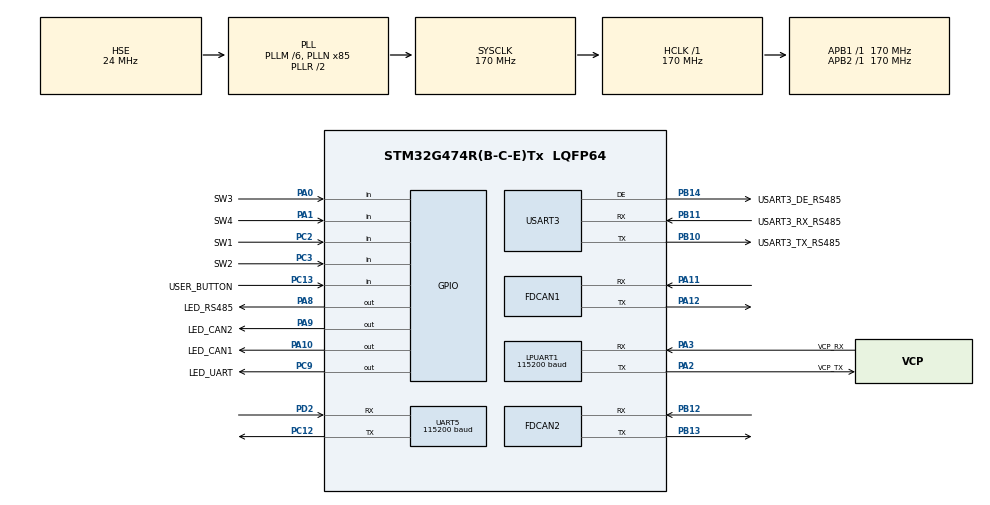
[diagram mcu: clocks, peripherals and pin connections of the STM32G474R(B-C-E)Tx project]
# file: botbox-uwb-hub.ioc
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Dma.Request0=USART3_RX
Dma.Request1=USART3_TX
Dma.Request2=UART5_RX
Dma.Request3=UART5_TX
Dma.UART5_RX.2.Direction=DMA_PERIPH_TO_MEMORY
Dma.UART5_RX.2.EventEnable=DISABLE
Dma.UART5_RX.2.Instance=DMA1_Channel3
Dma.UART5_RX.2.MemDataAlignment=DMA_MDATAALIGN_BYTE
Dma.UART5_RX.2.MemInc=DMA_MINC_ENABLE
Dma.UART5_RX.2.Mode=DMA_CIRCULAR
Dma.UART5_RX.2.PeriphDataAlignment=DMA_PDATAALIGN_BYTE
Dma.UART5_RX.2.PeriphInc=DMA_PINC_DISABLE
Dma.UART5_RX.2.Polarity=HAL_DMAMUX_REQ_GEN_RISING
Dma.UART5_RX.2.Priority=DMA_PRIORITY_LOW
Dma.UART5_RX.2.RequestNumber=1
Dma.UART5_RX.2.SignalID=NONE
Dma.UART5_RX.2.SyncEnable=DISABLE
Dma.UART5_RX.2.SyncPolarity=HAL_DMAMUX_SYNC_NO_EVENT
Dma.UART5_RX.2.SyncRequestNumber=1
Dma.UART5_RX.2.SyncSignalID=NONE
Dma.UART5_TX.3.Direction=DMA_MEMORY_TO_PERIPH
Dma.UART5_TX.3.EventEnable=DISABLE
Dma.UART5_TX.3.Instance=DMA1_Channel4
Dma.UART5_TX.3.MemDataAlignment=DMA_MDATAALIGN_BYTE
Dma.UART5_TX.3.MemInc=DMA_MINC_ENABLE
Dma.UART5_TX.3.Mode=DMA_NORMAL
Dma.UART5_TX.3.PeriphDataAlignment=DMA_PDATAALIGN_BYTE
Dma.UART5_TX.3.PeriphInc=DMA_PINC_DISABLE
Dma.UART5_TX.3.Polarity=HAL_DMAMUX_REQ_GEN_RISING
Dma.UART5_TX.3.Priority=DMA_PRIORITY_LOW
Dma.UART5_TX.3.RequestNumber=1
Dma.UART5_TX.3.SignalID=NONE
Dma.UART5_TX.3.SyncEnable=DISABLE
Dma.UART5_TX.3.SyncPolarity=HAL_DMAMUX_SYNC_NO_EVENT
Dma.UART5_TX.3.SyncRequestNumber=1
Dma.UART5_TX.3.SyncSignalID=NONE
Dma.USART3_RX.0.Direction=DMA_PERIPH_TO_MEMORY
Dma.USART3_RX.0.EventEnable=DISABLE
Dma.USART3_RX.0.Instance=DMA1_Channel1
Dma.USART3_RX.0.MemDataAlignment=DMA_MDATAALIGN_BYTE
Dma.USART3_RX.0.MemInc=DMA_MINC_ENABLE
Dma.USART3_RX.0.Mode=DMA_CIRCULAR
Dma.USART3_RX.0.PeriphDataAlignment=DMA_PDATAALIGN_BYTE
Dma.USART3_RX.0.PeriphInc=DMA_PINC_DISABLE
Dma.USART3_RX.0.Polarity=HAL_DMAMUX_REQ_GEN_RISING
Dma.USART3_RX.0.Priority=DMA_PRIORITY_LOW
Dma.USART3_RX.0.RequestNumber=1
Dma.USART3_RX.0.SignalID=NONE
Dma.USART3_RX.0.SyncEnable=DISABLE
Dma.USART3_RX.0.SyncPolarity=HAL_DMAMUX_SYNC_NO_EVENT
Dma.USART3_RX.0.SyncRequestNumber=1
Dma.USART3_RX.0.SyncSignalID=NONE
Dma.USART3_TX.1.Direction=DMA_MEMORY_TO_PERIPH
Dma.USART3_TX.1.EventEnable=DISABLE
Dma.USART3_TX.1.Instance=DMA1_Channel2
Dma.USART3_TX.1.MemDataAlignment=DMA_MDATAALIGN_BYTE
Dma.USART3_TX.1.MemInc=DMA_MINC_ENABLE
Dma.USART3_TX.1.Mode=DMA_NORMAL
Dma.USART3_TX.1.PeriphDataAlignment=DMA_PDATAALIGN_BYTE
Dma.USART3_TX.1.PeriphInc=DMA_PINC_DISABLE
Dma.USART3_TX.1.Polarity=HAL_DMAMUX_REQ_GEN_RISING
Dma.USART3_TX.1.Priority=DMA_PRIORITY_LOW
Dma.USART3_TX.1.RequestNumber=1
Dma.USART3_TX.1.SignalID=NONE
Dma.USART3_TX.1.SyncEnable=DISABLE
Dma.USART3_TX.1.SyncPolarity=HAL_DMAMUX_SYNC_NO_EVENT
Dma.USART3_TX.1.SyncRequestNumber=1
Dma.USART3_TX.1.SyncSignalID=NONE
FDCAN1.AutoRetransmission=ENABLE
FDCAN1.CalculateBaudRateNominal=500000
FDCAN1.CalculateTimeBitNominal=2000
FDCAN1.CalculateTimeQuantumNominal=41.666666666666664
FDCAN1.DataPrescaler=1
FDCAN1.DataSyncJumpWidth=3
FDCAN1.DataTimeSeg1=8
FDCAN1.DataTimeSeg2=3
FDCAN1.ExtFiltersNbr=1
FDCAN1.FrameFormat=FDCAN_FRAME_FD_BRS
FDCAN1.NominalPrescaler=1
FDCAN1.NominalSyncJumpWidth=10
FDCAN1.NominalTimeSeg1=37
FDCAN1.NominalTimeSeg2=10
FDCAN1.StdFiltersNbr=1
FDCAN2.AutoRetransmission=ENABLE
FDCAN2.CalculateBaudRateNominal=500000
FDCAN2.CalculateTimeBitNominal=2000
FDCAN2.CalculateTimeQuantumNominal=41.666666666666664
FDCAN2.DataPrescaler=1
FDCAN2.DataSyncJumpWidth=3
FDCAN2.DataTimeSeg1=8
FDCAN2.DataTimeSeg2=3
FDCAN2.ExtFiltersNbr=1
FDCAN2.FrameFormat=FDCAN_FRAME_FD_BRS
FDCAN2.NominalPrescaler=1
FDCAN2.NominalSyncJumpWidth=10
FDCAN2.NominalTimeSeg1=37
FDCAN2.NominalTimeSeg2=10
FDCAN2.StdFiltersNbr=1
FREERTOS.Tasks01=defaultTask,24,128,StartDefaultTask,Default,NULL,Dynamic,NULL,NULL
FREERTOS.configCHECK_FOR_STACK_OVERFLOW=2
FREERTOS.configENABLE_FPU=1
FREERTOS.configTOTAL_HEAP_SIZE=24576
FREERTOS.configUSE_MALLOC_FAILED_HOOK=1
LPUART1.BaudRate=115200
Mcu.Family=STM32G4
Mcu.Name=STM32G474R(B-C-E)Tx
Mcu.Package=LQFP64
NVIC.DMA1_Channel1_IRQn=true\:6\:0\:true\:false\:true\:true\:false\:true\:true
NVIC.DMA1_Channel2_IRQn=true\:6\:0\:true\:false\:true\:true\:false\:true\:true
NVIC.DMA1_Channel3_IRQn=true\:6\:0\:true\:false\:true\:true\:false\:true\:true
NVIC.DMA1_Channel4_IRQn=true\:6\:0\:true\:false\:true\:true\:false\:true\:true
NVIC.FDCAN1_IT0_IRQn=true\:5\:0\:false\:false\:true\:true\:true\:true\:true
NVIC.FDCAN1_IT1_IRQn=true\:5\:0\:false\:false\:true\:true\:true\:true\:true
NVIC.FDCAN2_IT0_IRQn=true\:5\:0\:false\:false\:true\:true\:true\:true\:true
NVIC.FDCAN2_IT1_IRQn=true\:5\:0\:false\:false\:true\:true\:true\:true\:true
NVIC.PriorityGroup=NVIC_PRIORITYGROUP_4
NVIC.TIM7_DAC_IRQn=true\:15\:0\:false\:false\:true\:false\:false\:true\:true
NVIC.TimeBase=TIM7_DAC_IRQn
NVIC.TimeBaseIP=TIM7
NVIC.UART5_IRQn=true\:6\:0\:true\:false\:true\:true\:true\:true\:true
NVIC.USART3_IRQn=true\:6\:0\:true\:false\:true\:true\:true\:true\:true
PA0.GPIO_Label=SW3
PA0.Signal=GPIO_Input
PA1.GPIO_Label=SW4
PA1.Signal=GPIO_Input
PA10.GPIO_Label=LED_CAN1
PA10.Signal=GPIO_Output
PA11.Mode=FDCAN_Activate
PA11.Signal=FDCAN1_RX
PA12.Mode=FDCAN_Activate
PA12.Signal=FDCAN1_TX
PA13.Mode=Serial_Wire
PA13.Signal=SYS_JTMS-SWDIO
PA14.Mode=Serial_Wire
PA14.Signal=SYS_JTCK-SWCLK
PA2.GPIO_Label=VCP_TX
PA2.Mode=Asynchronous
PA2.Signal=LPUART1_TX
PA3.GPIO_Label=VCP_RX
PA3.Mode=Asynchronous
PA3.Signal=LPUART1_RX
PA8.GPIO_Label=LED_RS485
PA8.Signal=GPIO_Output
PA9.GPIO_Label=LED_CAN2
PA9.Signal=GPIO_Output
PB10.GPIO_Label=USART3_TX_RS485
PB10.Mode=Asynchronous
PB10.Signal=USART3_TX
PB11.GPIO_Label=USART3_RX_RS485
PB11.Mode=Asynchronous
PB11.Signal=USART3_RX
PB12.Mode=FDCAN_Activate
PB12.Signal=FDCAN2_RX
PB13.Mode=FDCAN_Activate
PB13.Signal=FDCAN2_TX
PB14.GPIO_Label=USART3_DE_RS485
PB14.Mode=Hardware Flow Control (RS485)
PB14.Signal=USART3_DE
PC12.Mode=Asynchronous
PC12.Signal=UART5_TX
PC13.GPIO_Label=USER_BUTTON
PC13.Signal=GPIO_Input
PC14-OSC32_IN.Mode=LSE-External-Oscillator
PC14-OSC32_IN.Signal=RCC_OSC32_IN
PC15-OSC32_OUT.Mode=LSE-External-Oscillator
PC15-OSC32_OUT.Signal=RCC_OSC32_OUT
PC2.GPIO_Label=SW1
PC2.Signal=GPIO_Input
PC3.GPIO_Label=SW2
PC3.Signal=GPIO_Input
PC9.GPIO_Label=LED_UART
PC9.Signal=GPIO_Output
PD2.Mode=Asynchronous
PD2.Signal=UART5_RX
PF0-OSC_IN.Mode=HSE-External-Oscillator
PF0-OSC_IN.Signal=RCC_OSC_IN
PF1-OSC_OUT.Mode=HSE-External-Oscillator
PF1-OSC_OUT.Signal=RCC_OSC_OUT
ProjectManager.HeapSize=0x200
ProjectManager.StackSize=0x400
ProjectManager.TargetToolchain=CMake
RCC.ADC12Freq_Value=170000000
RCC.ADC345Freq_Value=170000000
RCC.AHBFreq_Value=170000000
RCC.APB1Freq_Value=170000000
RCC.APB1TimFreq_Value=170000000
RCC.APB2Freq_Value=170000000
RCC.APB2TimFreq_Value=170000000
RCC.CortexFreq_Value=170000000
RCC.EXTERNAL_CLOCK_VALUE=12288000
RCC.FDCANCLockSelection=RCC_FDCANCLKSOURCE_HSE
RCC.HCLKFreq_Value=170000000
RCC.HSE_VALUE=24000000
RCC.HSI48_VALUE=48000000
RCC.HSI_VALUE=16000000
RCC.PLLM=RCC_PLLM_DIV6
RCC.PLLN=85
RCC.PLLSourceVirtual=RCC_PLLSOURCE_HSE
RCC.SYSCLKFreq_VALUE=170000000
RCC.SYSCLKSource=RCC_SYSCLKSOURCE_PLLCLK
RCC.USBFreq_Value=170000000
RCC.VCOOutputFreq_Value=340000000
TIM2.Prescaler=169
UART5.BaudRate=115200
USART3.VirtualMode-Asynchronous=VM_ASYNC
USART3.VirtualMode-Hardware\ Flow\ Control\ (RS485)=VM_ASYNC
VP_FMAC_VS_FMAC.Mode=FMAC_Activate
VP_FREERTOS_VS_CMSIS_V2.Mode=CMSIS_V2
VP_SYS_VS_DBSignals.Mode=DisableDeadBatterySignals
VP_SYS_VS_tim7.Mode=TIM7
VP_TIM2_VS_ClockSourceINT.Mode=Internal
board=custom

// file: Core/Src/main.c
/* USER CODE BEGIN Header */
/**
  ******************************************************************************
  * @file           : main.c
  * @brief          : Main program body
  ******************************************************************************
  * @attention
  *
  * Copyright (c) 2026 STMicroelectronics.
  * All rights reserved.
  *
  * This software is licensed under terms that can be found in the LICENSE file
  * in the root directory of this software component.
  * If no LICENSE file comes with this software, it is provided AS-IS.
  *
  ******************************************************************************
  */
/* USER CODE END Header */
#include "main.h"
#include "cmsis_os.h"
#include "dma.h"
#include "fdcan.h"
#include "fmac.h"
#include "usart.h"
#include "tim.h"
#include "gpio.h"

void SystemClock_Config(void);
void MX_FREERTOS_Init(void);

int main(void)
{

  /* MCU Configuration--------------------------------------------------------*/

  /* Reset of all peripherals, Initializes the Flash interface and the Systick. */
  HAL_Init();

  /* Configure the system clock */
  SystemClock_Config();

  /* Initialize all configured peripherals */
  MX_GPIO_Init();
  MX_DMA_Init();
  MX_LPUART1_UART_Init();
  MX_FDCAN1_Init();
  MX_UART5_Init();
  MX_FMAC_Init();
  MX_TIM2_Init();
  MX_FDCAN2_Init();
  MX_USART3_UART_Init();

  /* Init scheduler */
  osKernelInitialize();  /* Call init function for freertos objects (in cmsis_os2.c) */
  MX_FREERTOS_Init();

  /* Start scheduler */
  osKernelStart();

  /* We should never get here as control is now taken by the scheduler */

  /* Infinite loop */
  while (1)
  {

  }
}

void SystemClock_Config(void)
{
  RCC_OscInitTypeDef RCC_OscInitStruct = {0};
  RCC_ClkInitTypeDef RCC_ClkInitStruct = {0};

  /** Configure the main internal regulator output voltage
  */
  HAL_PWREx_ControlVoltageScaling(PWR_REGULATOR_VOLTAGE_SCALE1_BOOST);

  /** Initializes the RCC Oscillators according to the specified parameters
  * in the RCC_OscInitTypeDef structure.
  */
  RCC_OscInitStruct.OscillatorType = RCC_OSCILLATORTYPE_HSE;
  RCC_OscInitStruct.HSEState = RCC_HSE_ON;
  RCC_OscInitStruct.PLL.PLLState = RCC_PLL_ON;
  RCC_OscInitStruct.PLL.PLLSource = RCC_PLLSOURCE_HSE;
  RCC_OscInitStruct.PLL.PLLM = RCC_PLLM_DIV6;
  RCC_OscInitStruct.PLL.PLLN = 85;
  RCC_OscInitStruct.PLL.PLLP = RCC_PLLP_DIV2;
  RCC_OscInitStruct.PLL.PLLQ = RCC_PLLQ_DIV2;
  RCC_OscInitStruct.PLL.PLLR = RCC_PLLR_DIV2;
  if (HAL_RCC_OscConfig(&RCC_OscInitStruct) != HAL_OK)
  {
    Error_Handler();
  }

  /** Initializes the CPU, AHB and APB buses clocks
  */
  RCC_ClkInitStruct.ClockType = RCC_CLOCKTYPE_HCLK|RCC_CLOCKTYPE_SYSCLK
                              |RCC_CLOCKTYPE_PCLK1|RCC_CLOCKTYPE_PCLK2;
  RCC_ClkInitStruct.SYSCLKSource = RCC_SYSCLKSOURCE_PLLCLK;
  RCC_ClkInitStruct.AHBCLKDivider = RCC_SYSCLK_DIV1;
  RCC_ClkInitStruct.APB1CLKDivider = RCC_HCLK_DIV1;
  RCC_ClkInitStruct.APB2CLKDivider = RCC_HCLK_DIV1;

  if (HAL_RCC_ClockConfig(&RCC_ClkInitStruct, FLASH_LATENCY_4) != HAL_OK)
  {
    Error_Handler();
  }
}

void HAL_TIM_PeriodElapsedCallback(TIM_HandleTypeDef *htim)
{
  if (htim->Instance == TIM7)
  {
    HAL_IncTick();
  }
}

void Error_Handler(void)
{
  __disable_irq();
  while (1)
  {
  }
}

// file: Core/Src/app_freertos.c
/* USER CODE BEGIN Header */
/**
  ******************************************************************************
  * File Name          : app_freertos.c
  * Description        : Code for freertos applications
  ******************************************************************************
  * @attention
  *
  * Copyright (c) 2026 STMicroelectronics.
  * All rights reserved.
  *
  * This software is licensed under terms that can be found in the LICENSE file
  * in the root directory of this software component.
  * If no LICENSE file comes with this software, it is provided AS-IS.
  *
  ******************************************************************************
  */
/* USER CODE END Header */

#include "FreeRTOS.h"
#include "task.h"
#include "main.h"
#include "cmsis_os.h"

/* USER CODE BEGIN Includes */
#include "app_main.h"
#include "fault.h"
/* USER CODE END Includes */

/* Definitions for defaultTask */
osThreadId_t defaultTaskHandle;
const osThreadAttr_t defaultTask_attributes = {
  .name = "defaultTask",
  .priority = (osPriority_t) osPriorityNormal,
  .stack_size = 128 * 4
};

void StartDefaultTask(void *argument);

void MX_FREERTOS_Init(void); /* (MISRA C 2004 rule 8.1) */

/* Hook prototypes */
void vApplicationStackOverflowHook(xTaskHandle xTask, signed char *pcTaskName);
void vApplicationMallocFailedHook(void);

/* USER CODE BEGIN 4 */
void vApplicationStackOverflowHook(xTaskHandle xTask, signed char *pcTaskName)
{
  (void)xTask;
  fault_panic(FAULT_STACK_OVERFLOW, (const char *)pcTaskName);
}
/* USER CODE END 4 */

/* USER CODE BEGIN 5 */
void vApplicationMallocFailedHook(void)
{
  fault_panic(FAULT_MALLOC_FAILED, NULL);
}
/* USER CODE END 5 */

void MX_FREERTOS_Init(void) {

  /* Create the thread(s) */
  /* creation of defaultTask */
  defaultTaskHandle = osThreadNew(StartDefaultTask, NULL, &defaultTask_attributes);

  /* USER CODE BEGIN RTOS_THREADS */
  app_main_init();
  /* USER CODE END RTOS_THREADS */

}

void StartDefaultTask(void *argument)
{
  /* USER CODE BEGIN StartDefaultTask */
  /* Infinite loop */
  for(;;)
  {
    osDelay(1000);
  }
  /* USER CODE END StartDefaultTask */
}
